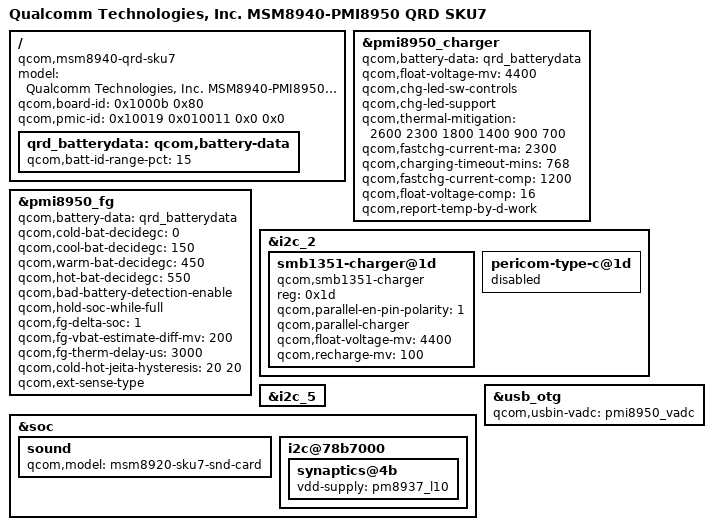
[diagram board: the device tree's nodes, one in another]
/*
 * Copyright (c) 2016, The Linux Foundation. All rights reserved.
 *
 * This program is free software; you can redistribute it and/or modify
 * it under the terms of the GNU General Public License version 2 and
 * only version 2 as published by the Free Software Foundation.
 *
 * This program is distributed in the hope that it will be useful,
 * but WITHOUT ANY WARRANTY; without even the implied warranty of
 * MERCHANTABILITY or FITNESS FOR A PARTICULAR PURPOSE.  See the
 * GNU General Public License for more details.
 */

/dts-v1/;

#include "msm8940.dtsi"
#include "msm8937-pmi8950-qrd-sku1.dtsi"
#include "msm8940-pinctrl.dtsi"

/ {
	model = "Qualcomm Technologies, Inc. MSM8940-PMI8950 QRD SKU7";
	compatible = "qcom,msm8940-qrd-sku7", "qcom,msm8940-qrd",
		   "qcom,msm8940", "qcom,qrd";
	qcom,board-id= <0x1000b 0x80>;
	qcom,pmic-id = <0x10019 0x010011 0x0 0x0>;
};

/ {
	qrd_batterydata: qcom,battery-data {
		qcom,batt-id-range-pct = <15>;
		#include "batterydata-qrd-jiade-4v4-3000mah.dtsi"
		#include "batterydata-qrd-veken-4v4-3000mah.dtsi"
		#include "batterydata-qrd-atl-4v4-3400mah.dtsi"
		//#include "batterydata-qrd-sku2-4v35-2590mah.dtsi"
	};
};

&pmi8950_charger {
	qcom,battery-data = <&qrd_batterydata>;
	qcom,float-voltage-mv = <4400>;
	qcom,chg-led-sw-controls;
	qcom,chg-led-support;
        qcom,thermal-mitigation = <2600 2300 1800 1400 900 700>;
	qcom,fastchg-current-ma = <2300>;
	qcom,charging-timeout-mins = <768>;
	qcom,fastchg-current-comp = <1200>;
	/* 11 for 4.2V, 16 for 4.1V */
	qcom,float-voltage-comp = <16>;
	qcom,report-temp-by-d-work;
	status = "okay";
};

&pmi8950_fg {
	qcom,battery-data = <&qrd_batterydata>;
	qcom,cold-bat-decidegc = <0>;
	qcom,cool-bat-decidegc = <150>;
	qcom,warm-bat-decidegc = <450>;
	qcom,hot-bat-decidegc = <550>;
	qcom,bad-battery-detection-enable;
	qcom,hold-soc-while-full;
	qcom,fg-delta-soc = <1>;
	qcom,fg-vbat-estimate-diff-mv = <200>;
	qcom,fg-therm-delay-us = <3000>;
	qcom,cold-hot-jeita-hysteresis = <20 20>;
	qcom,ext-sense-type;
};

&i2c_2 {
	//Parallel-charger configuration
	smb1351-charger@1d {
		compatible = "qcom,smb1351-charger";
		reg = <0x1d>;
		qcom,parallel-en-pin-polarity = <1>;
		qcom,parallel-charger;
		qcom,float-voltage-mv = <4400>;
		qcom,recharge-mv = <100>;
	};
};

&i2c_5 { /* BLSP2 QUP1 */
	/*nq@28 {
		compatible = "qcom,nq-nci";
		reg = <0x28>;
		qcom,nq-irq = <&tlmm 17 0x00>;
		qcom,nq-ven = <&tlmm 16 0x00>;
		qcom,nq-firm = <&tlmm 130 0x00>;
		qcom,nq-clkreq = <&pm8937_gpios 5 0x00>;
		interrupt-parent = <&tlmm>;
		qcom,clk-src = "BBCLK2";
		interrupts = <17 0>;
		interrupt-names = "nfc_irq";
		pinctrl-names = "nfc_active", "nfc_suspend";
		pinctrl-0 = <&nfc_int_active &nfc_disable_active>;
		pinctrl-1 = <&nfc_int_suspend &nfc_disable_suspend>;
		clocks = <&clock_gcc clk_bb_clk2_pin>;
		clock-names = "ref_clk";
	};*/
};

&soc {
	sound {
		qcom,model = "msm8920-sku7-snd-card";
	};

	i2c@78b7000 {
		synaptics@4b {
			vdd-supply = <&pm8937_l10>;
		};
	};
};

&i2c_2 {
	pericom-type-c@1d {
		status="disabled";
	};
};

&usb_otg {
	qcom,usbin-vadc = <&pmi8950_vadc>;
};
